# cslr_cache register map
Vendor: Texas Instruments
Peripheral module from a debugger description file (folder TCI6484_C6457).
Registers are 32-bit, access not given, reset 0x0 unless marked. A register's access mark holds for its fields unless they carry their own. Offsets are as the file gives them; lines under a group give offsets from that group; [hi:lo] are bit positions; {n}, {i} and the like mark numbered series; 'fields as' and 'values as' point back to an identical list; <NAME> marks a mode.

## CACHE — Cache - L1P, L1D, and L2
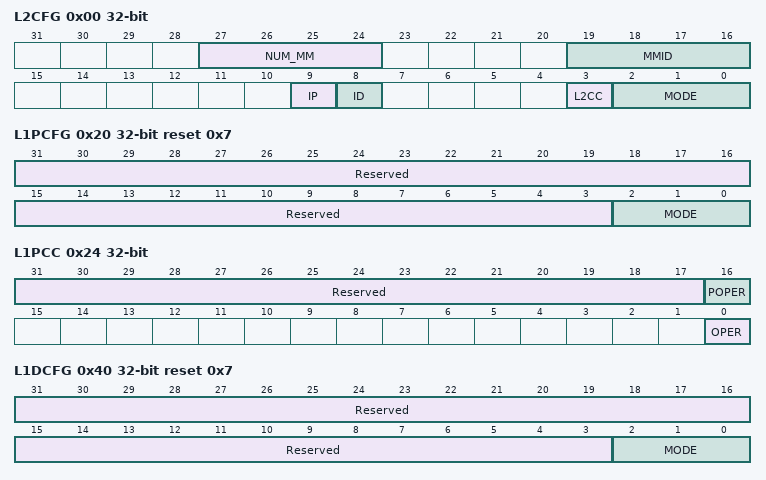
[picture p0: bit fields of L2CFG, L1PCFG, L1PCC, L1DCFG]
0x00 L2CFG — L2 Cache Configuration Register
  [27:24] NUM_MM ro — Number of Mega Modules on Chim
  [19:16] MMID ro — Mega Module ID value
  [9] IP wo — Global L1P Invalidate - Should use L1PINV instead
    0=NORMAL (Normal L1P Operation); 1=INVALIDATE (All L1P lines are invalidated)
  [8] ID wo — Global L1D Invalidate - Should use L1DINV instead
    0=NORMAL (Normal L1D Operation); 1=INVALIDATE (All L1D lines are invalidated)
  [3] L2CC rw — L2 Cache Controller - Controlls Enabled, Freeze
    0=ENABLED (L2 Cache is enabled); 1=FREEZE (L2 Cache is frozen)
  [2:0] MODE rw — L2 Mode Register
    0=OFF (L2 Cache turned off); 0=0K (L2 Cache turned off); 1=32K (L2 Cache Size 32K); 2=64K (L2 Cache Size 64K); 3=128K (L2 Cache Size 128K); 4=256K (L2 Cache Size 256K); 5=512K (L2 Cache Size 512K); 6=1024K (L2 Cache Size 1024K)
0x20 L1PCFG reset 0x7 — L1P Configuration Register
  [31:3] Reserved — (access N)
  [2:0] MODE rw — L1P Mode
    0=OFF (L1P Cache turned off); 0=0K (L1P Cache turned off); 1=4K (L1P Cache Size 4K); 2=8K (L1P Cache Size 8K); 3=16K (L1P Cache Size 16K); 4=32K (L2 Cache Size 32K)
0x24 L1PCC — L1P Cache Control Register
  [31:17] Reserved — (access N)
  [16] POPER ro — Previous Cache Operation Command - Normal / Freeze
    0=NORM (Normal Cache Operation); 1=FREEZE (Frozen/Freeze)
  [0] OPER rw — Cache Operation - Normal / Freeze
    0=NORM (Normal Cache Operation); 1=FREEZE (Frozen/Freeze)
0x40 L1DCFG reset 0x7 — L1D Configuration Register
  [31:3] Reserved — (access N)
  [2:0] MODE rw — L1D Mode
    0=OFF (L1D Cache turned off); 0=0K (L1D Cache turned off); 1=4K (L1D Cache Size 4K); 2=8K (L1D Cache Size 8K); 3=16K (L1D Cache Size 16K); 4=32K (L1D Cache Size 32K)
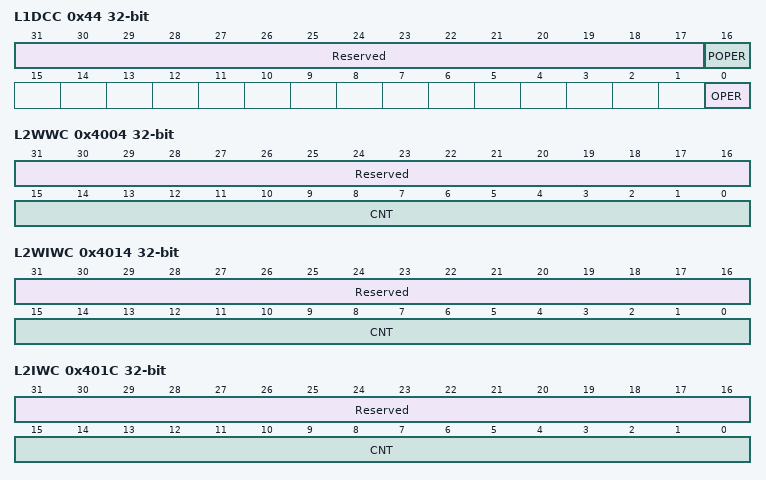
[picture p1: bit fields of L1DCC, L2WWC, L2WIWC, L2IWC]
0x44 L1DCC — L1D Cache Control Register
  [31:17] Reserved — (access N)
  [16] POPER ro — Previous Cache Operation Command - Normal / Freeze
    0=NORM (Normal Cache Operation); 1=FREEZE (Freeze Operation)
  [0] OPER rw — Cache Operation - Normal / Freeze
    0=NORM (Normal Cache Operation); 1=FREEZE (Freeze Operation)
0x4000 L2WBAR rw — L2 Writeback Base Address - For Block Writebacks
  [31:0] ADDR — Base Writeback Address - Default is last used? N/A?
0x4004 L2WWC — L2 Writeback Word Count Register
  [31:16] Reserved — (access N)
  [15:0] CNT rw — L2 Writeback Word Count Field
0x4010 L2WIBAR rw — L2 Writeback & Invalidate Base Address - For Block Writebacks
  [31:0] ADDR — Base Writeback & Invalidate Address - Default is last used? N/A?
0x4014 L2WIWC — L2 Writeback & Invalidate Word Count Register
  [31:16] Reserved — (access N)
  [15:0] CNT rw — L2 Writeback & Invalidate Word Count Field
0x4018 L2IBAR rw — L2 Invalidate Base Address - For Block Writebacks
  [31:0] ADDR — Base Invalidate Address - Default is last used? N/A?
0x401C L2IWC — L2 Invalidate Word Count Register
  [31:16] Reserved — (access N)
  [15:0] CNT rw — L2 Invalidate Word Count Field
0x4020 L1PIBAR rw — L1P Invalidate Base Address - For Block Writebacks
  [31:0] ADDR — L1P Base Invalidate Address - Default is last used? N/A?
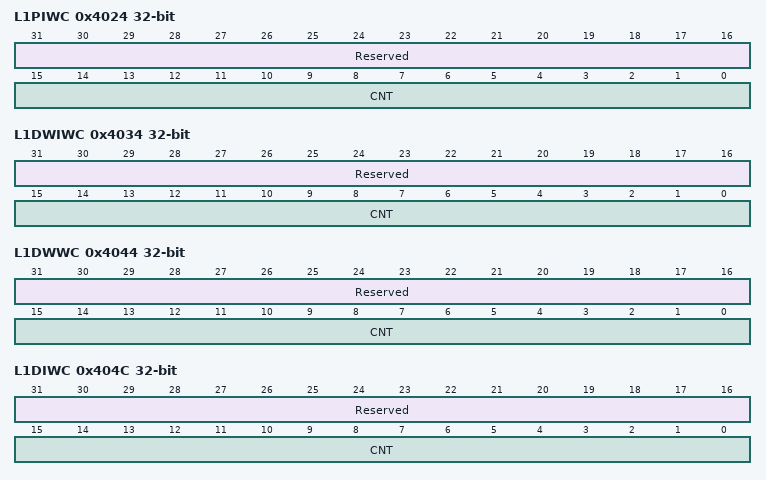
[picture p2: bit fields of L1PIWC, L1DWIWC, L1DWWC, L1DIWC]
0x4024 L1PIWC — L1P Invalidate Word Count Register
  [31:16] Reserved — (access N)
  [15:0] CNT rw — L1P Invalidate Word Count Field
0x4030 L1DWIBAR rw — L1D Writeback & Invalidate Base Address - For Block Writebacks
  [31:0] ADDR — L1D Base Writeback & Invalidate Address - Default is last used? N/A?
0x4034 L1DWIWC — L1D Writeback & Invalidate Word Count Register
  fields as L2WIWC
0x4040 L1DWBAR rw — L1D Writeback Base Address - For Block Writebacks
  [31:0] ADDR — L1D Base Writeback Address - Default is last used? N/A?
0x4044 L1DWWC — L1D Writeback Word Count Register
  [31:16] Reserved — (access N)
  [15:0] CNT rw — L1D Writeback Word Count Field
0x4048 L1DIBAR rw — L1D Invalidate Base Address - For Block Writebacks
  [31:0] ADDR — L1D Base Invalidate Address - Default is last used? N/A?
0x404C L1DIWC — L1D Invalidate Word Count Register
  [31:16] Reserved — (access N)
  [15:0] CNT rw — L1D Invalidate Word Count Field
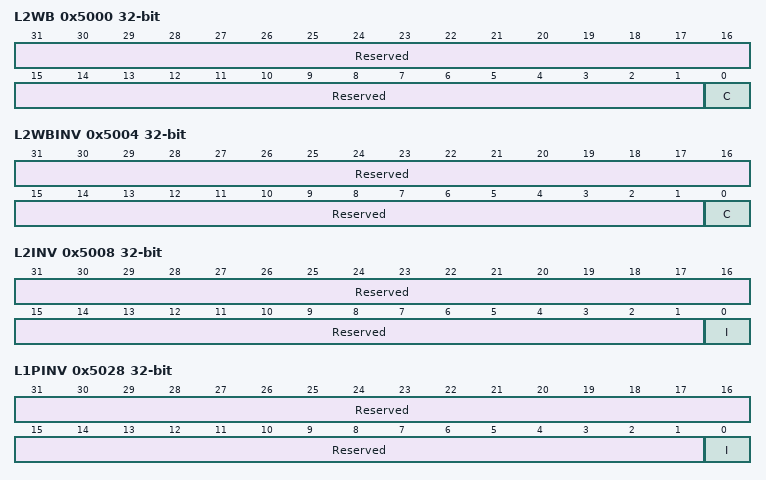
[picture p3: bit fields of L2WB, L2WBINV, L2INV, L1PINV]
0x5000 L2WB — L2 Global Writeback Register - Write 1 to generate global write back - it will remain 1 until global writeback is completed then it will become 0
  [31:1] Reserved — (access N)
  [0] C rw — Writeback Register - Issue Writeback and Read Status of Writeback
    1=WB (Issue Writeback); 0=NORM (Writeback Completed)
0x5004 L2WBINV — L2 Global Writeback & Invalidate Register - Write 1 to generate global WB & INV - it will remain 1 until global writeback is completed then it will become 0
  [31:1] Reserved — (access N)
  [0] C rw — Writeback & Invalidate Command and Status field - Issue WB & INV and Read Status of WB & INV
    1=WBINV (Issue WB&INV); 0=NORM (WB & INV Completed)
0x5008 L2INV — L2 Global Invalidate Register - Write 1 to generate global INV - it will remain 1 until global writeback is completed then it will become 0
  [31:1] Reserved — (access N)
  [0] I rw — Invalidate Command and Status field - Issue INV and Read Status of INV
    1=INV (Issue Invalidate Command); 0=NORM (INV Command Completed)
0x5028 L1PINV — L1P Global Invalidate Register - Write 1 to generate global INV - it will remain 1 until global writeback is completed then it will become 0
  [31:1] Reserved — (access N)
  [0] I rw — Invalidate Command and Status field - Issue INV and Read Status of INV
    1=INV (Issue Invalidate Command); 0=NORM (INV Command Completed); 0=?
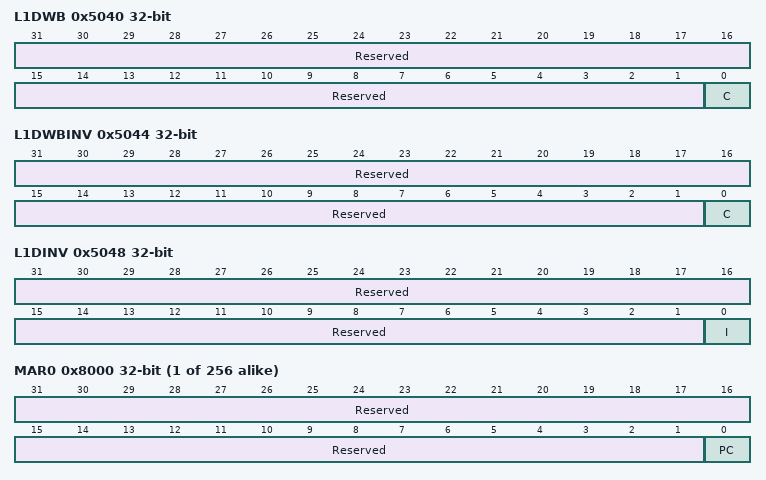
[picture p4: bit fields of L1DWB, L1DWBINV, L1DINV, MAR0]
0x5040 L1DWB — L1D Global Writeback Register - Write 1 to generate global write back - it will remain 1 until global writeback is completed then it will become 0
  fields as L2WB
0x5044 L1DWBINV — L1D Global Writeback & Invalidate Register - Write 1 to generate global WB & INV - it will remain 1 until global writeback is completed then it will become 0
  fields as L2WBINV
0x5048 L1DINV — L1D Global Invalidate Register - Write 1 to generate global INV - it will remain 1 until global writeback is completed then it will become 0
  fields as L2INV
{0x8000+4i} MAR{i} (i=0..255) — Memory Attribute Register, MAR0 - Local SRAM, MAR1 - Internal Config, MAR2 - External Config, MAR3 - MAR255, Starting address 0x03000000, each register takes care of 0xffffff bytes
  [31:1] Reserved — (access N)
  [0] PC ro — Program Cache Setting - 0 Not Cacheable, 1 Cacheable
    1=CACHEABLE (Address is Cacheable); 0=NOT_CACHEABLE (Address is not Cacheable)
